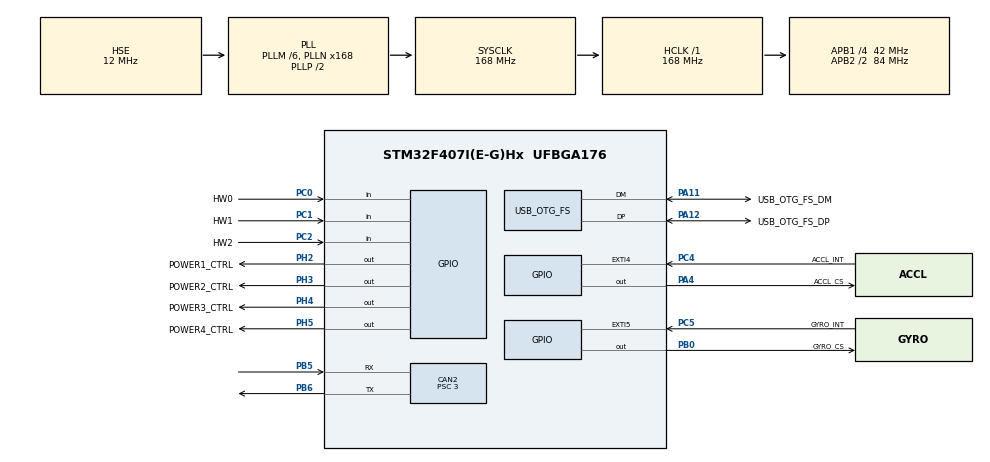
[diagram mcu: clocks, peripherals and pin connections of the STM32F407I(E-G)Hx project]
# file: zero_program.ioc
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CAN2.BS1=CAN_BS1_12TQ
CAN2.CalculateBaudRate=1000000
CAN2.CalculateTimeBit=1000
CAN2.CalculateTimeQuantum=71.42857142857143
CAN2.Prescaler=3
CAN2.TXFP=ENABLE
FREERTOS.Tasks01=defaultTask,24,128,StartDefaultTask,Default,NULL,Dynamic,NULL,NULL
FREERTOS.configGENERATE_RUN_TIME_STATS=1
FREERTOS.configUSE_NEWLIB_REENTRANT=1
FREERTOS.configUSE_STATS_FORMATTING_FUNCTIONS=1
FREERTOS.configUSE_TRACE_FACILITY=1
Mcu.Family=STM32F4
Mcu.Name=STM32F407I(E-G)Hx
Mcu.Package=UFBGA176
NVIC.CAN2_RX0_IRQn=true\:5\:0\:false\:false\:true\:true\:true\:true\:true
NVIC.CAN2_RX1_IRQn=true\:5\:0\:false\:false\:true\:true\:true\:true\:true
NVIC.OTG_FS_IRQn=true\:5\:0\:false\:false\:true\:true\:false\:true\:true
NVIC.PriorityGroup=NVIC_PRIORITYGROUP_4
NVIC.TIM6_DAC_IRQn=true\:0\:0\:false\:false\:true\:false\:false\:true\:true
NVIC.TimeBase=TIM6_DAC_IRQn
NVIC.TimeBaseIP=TIM6
PA11.GPIO_Label=USB_OTG_FS_DM
PA11.Mode=Device_Only
PA11.Signal=USB_OTG_FS_DM
PA12.GPIO_Label=USB_OTG_FS_DP
PA12.Mode=Device_Only
PA12.Signal=USB_OTG_FS_DP
PA13.Mode=Serial_Wire
PA13.Signal=SYS_JTMS-SWDIO
PA14.Mode=Serial_Wire
PA14.Signal=SYS_JTCK-SWCLK
PA4.GPIO_Label=ACCL_CS
PA4.GPIO_PuPd=GPIO_PULLUP
PA4.GPIO_Speed=GPIO_SPEED_FREQ_MEDIUM
PA4.PinState=GPIO_PIN_SET
PA4.Signal=GPIO_Output
PB0.GPIO_Label=GYRO_CS
PB0.GPIO_PuPd=GPIO_PULLUP
PB0.GPIO_Speed=GPIO_SPEED_FREQ_MEDIUM
PB0.PinState=GPIO_PIN_SET
PB0.Signal=GPIO_Output
PB5.Mode=CAN_Activate
PB5.Signal=CAN2_RX
PB6.Mode=CAN_Activate
PB6.Signal=CAN2_TX
PC0.GPIO_Label=HW0
PC0.Signal=GPIO_Input
PC1.GPIO_Label=HW1
PC1.Signal=GPIO_Input
PC2.GPIO_Label=HW2
PC2.Signal=GPIO_Input
PC4.GPIO_Label=ACCL_INT
PC4.GPIO_PuPd=GPIO_PULLUP
PC4.Signal=GPXTI4
PC5.GPIO_Label=GYRO_INT
PC5.GPIO_PuPd=GPIO_PULLUP
PC5.Signal=GPXTI5
PH0-OSC_IN.Mode=HSE-External-Oscillator
PH0-OSC_IN.Signal=RCC_OSC_IN
PH1-OSC_OUT.Mode=HSE-External-Oscillator
PH1-OSC_OUT.Signal=RCC_OSC_OUT
PH2.GPIO_Label=POWER1_CTRL
PH2.PinState=GPIO_PIN_SET
PH2.Signal=GPIO_Output
PH3.GPIO_Label=POWER2_CTRL
PH3.PinState=GPIO_PIN_SET
PH3.Signal=GPIO_Output
PH4.GPIO_Label=POWER3_CTRL
PH4.PinState=GPIO_PIN_SET
PH4.Signal=GPIO_Output
PH5.GPIO_Label=POWER4_CTRL
PH5.PinState=GPIO_PIN_SET
PH5.Signal=GPIO_Output
ProjectManager.HeapSize=0x200
ProjectManager.StackSize=0x400
ProjectManager.TargetToolchain=MDK-ARM V5
RCC.48MHZClocksFreq_Value=48000000
RCC.AHBFreq_Value=168000000
RCC.APB1CLKDivider=RCC_HCLK_DIV4
RCC.APB1Freq_Value=42000000
RCC.APB1TimFreq_Value=84000000
RCC.APB2CLKDivider=RCC_HCLK_DIV2
RCC.APB2Freq_Value=84000000
RCC.APB2TimFreq_Value=168000000
RCC.CortexFreq_Value=168000000
RCC.HCLKFreq_Value=168000000
RCC.HSE_VALUE=12000000
RCC.HSI_VALUE=16000000
RCC.LSE_VALUE=32768
RCC.PLLM=6
RCC.PLLN=168
RCC.PLLQ=7
RCC.SYSCLKFreq_VALUE=168000000
RCC.SYSCLKSource=RCC_SYSCLKSOURCE_PLLCLK
RCC.VCOOutputFreq_Value=336000000
USB_DEVICE.CLASS_NAME_FS=CDC
USB_DEVICE.VirtualMode-CDC_FS=Cdc
USB_DEVICE.VirtualModeFS=Cdc_FS
USB_OTG_FS.VirtualMode=Device_Only
VP_FREERTOS_VS_CMSIS_V2.Mode=CMSIS_V2
VP_SYS_VS_tim6.Mode=TIM6
VP_USB_DEVICE_VS_USB_DEVICE_CDC_FS.Mode=CDC_FS
board=custom

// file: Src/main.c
/* USER CODE BEGIN Header */
/**
  ******************************************************************************
  * @file           : main.c
  * @brief          : Main program body
  ******************************************************************************
  * @attention
  *
  * <h2><center>&copy; Copyright (c) 2020 STMicroelectronics.
  * All rights reserved.</center></h2>
  *
  * This software component is licensed by ST under BSD 3-Clause license,
  * the "License"; You may not use this file except in compliance with the
  * License. You may obtain a copy of the License at:
  *                        opensource.org/licenses/BSD-3-Clause
  *
  ******************************************************************************
  */
/* USER CODE END Header */
#include "main.h"
#include "cmsis_os.h"
#include "can.h"
#include "usb_device.h"
#include "gpio.h"

void SystemClock_Config(void);
void MX_FREERTOS_Init(void);

int main(void)
{

  /* MCU Configuration--------------------------------------------------------*/

  /* Reset of all peripherals, Initializes the Flash interface and the Systick. */
  HAL_Init();

  /* Configure the system clock */
  SystemClock_Config();

  /* Initialize all configured peripherals */
  MX_GPIO_Init();
  MX_CAN2_Init();

  /* Init scheduler */
  osKernelInitialize();  /* Call init function for freertos objects (in cmsis_os2.c) */
  MX_FREERTOS_Init();

  /* Start scheduler */
  osKernelStart();

  /* We should never get here as control is now taken by the scheduler */

  /* Infinite loop */
  while (1)
  {

  }
}

void SystemClock_Config(void)
{
  RCC_OscInitTypeDef RCC_OscInitStruct = {0};
  RCC_ClkInitTypeDef RCC_ClkInitStruct = {0};

  /** Configure the main internal regulator output voltage
  */
  __HAL_RCC_PWR_CLK_ENABLE();
  __HAL_PWR_VOLTAGESCALING_CONFIG(PWR_REGULATOR_VOLTAGE_SCALE1);

  /** Initializes the RCC Oscillators according to the specified parameters
  * in the RCC_OscInitTypeDef structure.
  */
  RCC_OscInitStruct.OscillatorType = RCC_OSCILLATORTYPE_HSE;
  RCC_OscInitStruct.HSEState = RCC_HSE_ON;
  RCC_OscInitStruct.PLL.PLLState = RCC_PLL_ON;
  RCC_OscInitStruct.PLL.PLLSource = RCC_PLLSOURCE_HSE;
  RCC_OscInitStruct.PLL.PLLM = 6;
  RCC_OscInitStruct.PLL.PLLN = 168;
  RCC_OscInitStruct.PLL.PLLP = RCC_PLLP_DIV2;
  RCC_OscInitStruct.PLL.PLLQ = 7;
  if (HAL_RCC_OscConfig(&RCC_OscInitStruct) != HAL_OK)
  {
    Error_Handler();
  }

  /** Initializes the CPU, AHB and APB buses clocks
  */
  RCC_ClkInitStruct.ClockType = RCC_CLOCKTYPE_HCLK|RCC_CLOCKTYPE_SYSCLK
                              |RCC_CLOCKTYPE_PCLK1|RCC_CLOCKTYPE_PCLK2;
  RCC_ClkInitStruct.SYSCLKSource = RCC_SYSCLKSOURCE_PLLCLK;
  RCC_ClkInitStruct.AHBCLKDivider = RCC_SYSCLK_DIV1;
  RCC_ClkInitStruct.APB1CLKDivider = RCC_HCLK_DIV4;
  RCC_ClkInitStruct.APB2CLKDivider = RCC_HCLK_DIV2;

  if (HAL_RCC_ClockConfig(&RCC_ClkInitStruct, FLASH_LATENCY_5) != HAL_OK)
  {
    Error_Handler();
  }
}

void HAL_TIM_PeriodElapsedCallback(TIM_HandleTypeDef *htim)
{
  if (htim->Instance == TIM6)
  {
    HAL_IncTick();
  }
}

void Error_Handler(void)
{
}

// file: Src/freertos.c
/* USER CODE BEGIN Header */
/**
  ******************************************************************************
  * File Name          : freertos.c
  * Description        : Code for freertos applications
  ******************************************************************************
  * @attention
  *
  * <h2><center>&copy; Copyright (c) 2026 STMicroelectronics.
  * All rights reserved.</center></h2>
  *
  * This software component is licensed by ST under Ultimate Liberty license
  * SLA0044, the "License"; You may not use this file except in compliance with
  * the License. You may obtain a copy of the License at:
  *                             www.st.com/SLA0044
  *
  ******************************************************************************
  */
/* USER CODE END Header */

#include "FreeRTOS.h"
#include "task.h"
#include "main.h"
#include "cmsis_os.h"

/* USER CODE BEGIN Includes */
#include "task/user_task.h"

/* USER CODE END Includes */

/* USER CODE BEGIN Variables */
osThreadId_t initTaskHandle;

/* USER CODE END Variables */
/* Definitions for defaultTask */
osThreadId_t defaultTaskHandle;
const osThreadAttr_t defaultTask_attributes = {
  .name = "defaultTask",
  .stack_size = 128 * 4,
  .priority = (osPriority_t) osPriorityNormal,
};

void StartDefaultTask(void *argument);

extern void MX_USB_DEVICE_Init(void);
void MX_FREERTOS_Init(void); /* (MISRA C 2004 rule 8.1) */

/* Hook prototypes */
void configureTimerForRunTimeStats(void);
unsigned long getRunTimeCounterValue(void);

/* USER CODE BEGIN 1 */
/* Functions needed when configGENERATE_RUN_TIME_STATS is on */
__weak void configureTimerForRunTimeStats(void)
{

}

__weak unsigned long getRunTimeCounterValue(void)
{
return 0;
}
/* USER CODE END 1 */

void MX_FREERTOS_Init(void) {

  /* Create the thread(s) */
  /* creation of defaultTask */
  defaultTaskHandle = osThreadNew(StartDefaultTask, NULL, &defaultTask_attributes);

  /* USER CODE BEGIN RTOS_THREADS */
  initTaskHandle = osThreadNew(Task_Init, NULL, &attr_init);
  /* USER CODE END RTOS_THREADS */

}

void StartDefaultTask(void *argument)
{
  /* init code for USB_DEVICE */
  MX_USB_DEVICE_Init();
  for(;;)
  {
    osDelay(1);
  }
}
